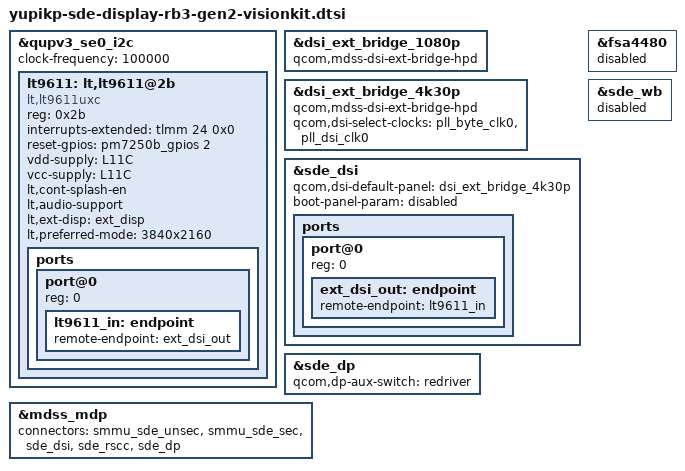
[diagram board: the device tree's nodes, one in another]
// SPDX-License-Identifier: BSD-3-Clause
/*
 * Copyright (c) Qualcomm Technologies, Inc. and/or its subsidiaries.
 */

#include "yupik-sde-display.dtsi"

/*==============================*/
/*     Display Related Start    */
/*==============================*/
&qupv3_se0_i2c {
	clock-frequency = <100000>;
	status = "okay";

	lt9611: lt,lt9611@2b {
		compatible = "lt,lt9611uxc";
		reg = <0x2b>;

		interrupt-names = "lt_irq";
		interrupts-extended = <&tlmm 24 0x0>;
		reset-gpios = <&pm7250b_gpios 2 0>;

		vdd-supply = <&L11C>;
		vcc-supply = <&L11C>;

		lt,cont-splash-en;
		lt,audio-support;
		lt,ext-disp = <&ext_disp>;
		lt,preferred-mode = "3840x2160";

		ports {
			#address-cells = <1>;
			#size-cells = <0>;

			port@0 {
				reg = <0>;

				lt9611_in: endpoint {
					remote-endpoint = <&ext_dsi_out>;
				};
			};
		};
	};
};

&dsi_ext_bridge_1080p {
	qcom,mdss-dsi-ext-bridge-hpd;
};

&dsi_ext_bridge_4k30p {
	qcom,mdss-dsi-ext-bridge-hpd;
	qcom,dsi-select-clocks = "pll_byte_clk0", "pll_dsi_clk0";
};

&sde_dsi {
	/delete-property/ lab-supply;
	/delete-property/ ibb-supply;

	qcom,dsi-default-panel = <&dsi_ext_bridge_4k30p>;
	boot-panel-param = "disabled";

	ports {
		#address-cells = <1>;
		#size-cells = <0>;

		port@0 {
			reg = <0>;
			ext_dsi_out: endpoint {
				remote-endpoint = <&lt9611_in>;
			};
		};
	};
};

&fsa4480 {
	status = "disabled";
};

&sde_dp {
	qcom,dp-aux-switch = <&redriver>;
};

&sde_wb {
	status = "disabled";
};

&mdss_mdp {
	connectors = <&smmu_sde_unsec &smmu_sde_sec &sde_dsi &sde_rscc &sde_dp>;
};
